# PIC32MK1024GPK064 device description
Architecture: MIPS; Family: PIC32MK; Series: PIC32MK
Registers are 32-bit, read-write, no defined reset value unless marked. A register's access mark holds for its fields unless they carry their own. Offsets are from the block's base; [hi:lo] are bit positions; {n}, {i} and the like mark numbered series; 'fields as' and 'values as' point back to an identical list; <NAME> marks a mode.

## CRU
Instances: CRU 0x1f801200 in periph_pb1_std
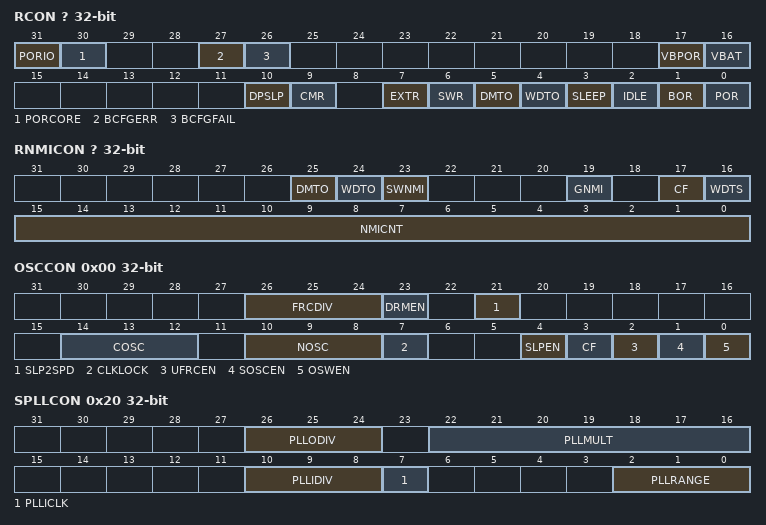
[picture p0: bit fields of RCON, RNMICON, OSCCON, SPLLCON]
? RCON size not given access not given — Reset Control Register
  [31] PORIO — I/O Voltage POR Flag bit
    1=RESET (A Power-up Reset has occurred due to I/O Voltage); 0=NORESET (A Power-up Reset has not occurred due to I/O Voltage)
  [30] PORCORE — Core Voltage POR Flag bit
    1=RESET (A Power-up Reset has occurred due to Core Voltage); 0=NORESET (A Power-up Reset has not occurred due to Core Voltage)
  [27] BCFGERR — Primary Configuration Registers Error Flag bit
    1=ERROR (An error occurred during a read of the primary configuration registers); 0=NOERROR (No error occurred during a read of the primary configuration registers)
  [26] BCFGFAIL — Primary/Secondary Configuration Registers Error Flag bit
    1=ERROR (An error occurred during a read of the primary and alternate configuration registers); 0=NOERROR (No error occurred during a read of the primary and alternate configuration registers)
  [17] VBPOR — VBPOR Mode Flag bit
    1=POR (A VBAT domain POR has occurred); 0=NOPOR (A VBAT domain POR has not occurred)
  [16] VBAT — VBAT Mode Flag bit
    1=POR (A POR exit from VBAT has occurred); 0=NOPOR (A POR exit from VBAT has not occurred)
  [10] DPSLP — Deep Sleep Mode Flag bit
    1=SLEEP (Deep Sleep mode has occurred); 0=NOSLEEP (Deep Sleep mode has not occurred)
  [9] CMR — Configuration Mismatch Reset Flag bit
    1=RESET (A Configuration Mismatch Reset has occurred); 0=NORESET (A Configuration Mismatch Reset has not occurred)
  [7] EXTR — External Reset (MCLR) Pin Flag bit
    1=RESET (Master Clear (pin) Reset has occurred); 0=NORESET (Master Clear (pin) Reset has not occurred)
  [6] SWR — Software Reset Flag bit
    1=RESET (Software Reset was executed); 0=NORESET (Software Reset was not executed)
  [5] DMTO — Deadman Timer Time-out Flag bit
    1=TIMEOUT (A DMT time-out has occurred); 0=NOTIMEOUT (A DMT time-out has not occurred)
  [4] WDTO — Watchdog Timer Time-out Flag bit
    1=TIMEOUT (WDT Time-out has occurred); 0=NOTIMEOUT (WDT Time-out has not occurred)
  [3] SLEEP — Wake From Sleep Flag bit
    1=SLEEP (Device was in Sleep mode); 0=NOSLEEP (Device was not in Sleep mode)
  [2] IDLE — Wake From Idle Flag bit
    1=IDLE (Device was in Idle mode); 0=NOIDLE (Device was not in Idle mode)
  [1] BOR — Brown-out Reset Flag bit
    1=RESET (Brown-out Reset has occurred); 0=NORESET (Brown-out Reset has not occurred)
  [0] POR — Power-on Reset Flag bit
    1=RESET (Power-on Reset has occurred); 0=NORESET (Power-on Reset has NOT occurred)
? RSWRST size not given access not given — Software Reset Register
  [0] SWRST — Enable software Reset event
    1=RESET (Enable software Reset event); 0=NORESET (No effect)
? RNMICON size not given access not given — Non-maskable Interrupt Control Register
  [25] DMTO — Deadman Timer Time-out Flag bit
    1=TIMEOUT (DMT time-out has occurred and caused a NMI); 0=NO_TIMEOUT (DMT time-out has not occurred)
  [24] WDTO — Watchdog Timer Time-Out Flag bit
    1=TIMEOUT (WDT time-out has occurred and caused a NMI); 0=NO_TIMEOUT (WDT time-out has not occurred)
  [23] SWNMI — Software NMI Trigger
    1=GENERATE_NMI (An NMI will be generated); 0=NO_NMI (An NMI will not be generated)
  [19] GNMI — General NMI bit
    1=EVENT (A general NMI event has been detected or a user-initiated NMI event has occurred); 0=NOEVENT (A general NMI event has not been detected)
  [17] CF — Clock Fail Detect bit
    1=CLKFAIL (FSCM has detected clock failure and caused an NMI); 0=NOCKFAIL (FSCM has not detected clock failure)
  [16] WDTS — Watchdog Timer Time-out in Sleep Mode Flag bit
    1=TIMEOUT (WDT time-out has occurred during Sleep mode and caused a wake-up from sleep); 0=NOTIMEOUT (WDT time-out has not occurred during Sleep mode)
  [15:0] NMICNT — NMI Reset Counter Value bits
    0=NODELAY (No delay between NMI assertion and device Reset event)
? PWRCON size not given access not given — Power Control Register
  [0] VREGS — Internal Voltage Regulator Stand-by Enable bit
    1=ACTIVE (Voltage regulator will remain active during Sleep); 0=STANDBY (Voltage regulator will go to Stand-by mode during Sleep)
0x00 OSCCON — Oscillator Control Register
  [26:24] FRCDIV — Internal Fast RC Oscillator Clock Divider bits
    7=DIV256 (FRC divided by 256); 6=DIV64 (FRC divided by 64); 5=DIV32 (FRC divided by 32); 4=DIV16 (FRC divided by 16); 3=DIV8 (FRC divided by 8); 2=DIV4 (FRC divided by 4); 1=DIV2 (FRC divided by 2); 0=DIV1 (FRC divided by 1 (default setting))
  [23] DRMEN — Dream Mode Enable bit
    1=Dream mode is enabled; 0=Dream mode is disabled
  [21] SLP2SPD — Sleep Two-speed Start-up Control bit
    1=Use FRC as SYSCLK until the selected clock is ready; 0=Use the selected clock directly
  [14:12] COSC — Current Oscillator Selection bits
    6=Backup Fast RC (BFRC) Oscillator; 5=Internal Low-Power RC (LPRC) Oscillator; 4=Secondary Oscillator (SOSC); 3=USB PLL (UPLL) input clock and divider are set by UPLLCON; 2=Primary Oscillator (Posc) (HS or EC); 1=System PLL (SPLL) input clock and divider set by SPLLCON; 0=Internal Fast RC (FRC) Oscillator divided by FRCDIV bits (FRCDIV) supports FRN divided by N
  [10:8] NOSC — New Oscillator Selection bits
    6=Backup Fast RC (BFRC) Oscillator; 5=Internal Low-Power RC (LPRC) Oscillator; 4=Secondary Oscillator; 3=USB PLL (UPLL) input clock and divider are set by UPLLCON; 2=Primary Oscillator (Posc) (HS or EC); 1=System PLL (SPLL) input clock and divider set by SPLLCON; 0=Internal Fast RC (FRC) Oscillator divided by FRCDIV bits (FRCDIV) supports FRN divided by N
  [7] CLKLOCK — Clock Selection Lock Enable bit
    1=Clock and PLL selections are locked; 0=Clock and PLL selections are not locked and may be modified
  [4] SLPEN — Sleep Mode Enable bit
    1=Device will enter Sleep mode when a WAIT instruction is executed; 0=Device will enter Idle mode when a WAIT instruction is executed
  [3] CF — Clock Fail Detect bit
    1=FSCM has detected a clock failure; 0=No clock failure has been detected
  [2] UFRCEN — USB FRC Sleep Clock Enable bit
    1=FRC is the USB input clock for wake from Sleep mode; 0=USB input clock is determined by the UPOSCEN bit (UPLLCON)
  [1] SOSCEN — Secondary Oscillator (
    1=Enable Secondary Oscillator; 0=Disable Secondary Oscillator
  [0] OSWEN — Oscillator Switch Enable bit
    1=Initiate an oscillator switch to selection specified by NOSC bits; 0=Oscillator switch is complete
0x10 OSCTUN — FRC Tuning Register
  [5:0] TUN — FRC Oscillator Tuning bits
    63=+1.453%; 32=0.000% (Nominal Center Frequency; 0=-1.500%
0x20 SPLLCON — System PLL Control Register
  [26:24] PLLODIV — System PLL Output Clock Divider bits
    5=DIV_32 (PLL Divide by 32); 4=DIV_16 (PLL Divide by 16); 3=DIV_8 (PLL Divide by 8); 2=DIV_4 (PLL Divide by 4); 1=DIV_2 (PLL Divide by 2)
  [22:16] PLLMULT — System PLL Multiplier bits
    {v}=MUL_{v+1} (Multiply by {v+1}) (v=0..127)
  [10:8] PLLIDIV — System PLL Input Clock Divider bits
    {v}=DIV_{v+1} (Divide by {v+1}) (v=0..7)
  [7] PLLICLK — System PLL Input Clock Source bit
    1=FRC is selected as the input to the System PLL; 0=Posc is selected as the input to the System PLL
  [2:0] PLLRANGE — System PLL Frequency Range Selection bits
    6=RANGE_54_64_MHZ (54-64 MHz); 5=RANGE_34_64_MHZ (34-64 MHz); 4=RANGE_21_42_MHZ (21-42 MHz); 3=RANGE_13_26_MHZ (13-26 MHz); 2=RANGE_8_16_MHZ (8-16 MHz); 1=RANGE_5_10_MHZ (5-10 MHz); 0=Bypass
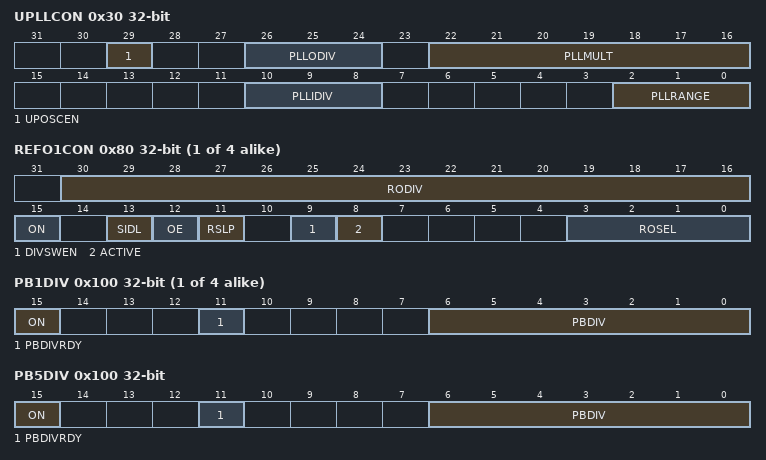
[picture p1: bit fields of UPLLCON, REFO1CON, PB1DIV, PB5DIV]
0x30 UPLLCON — USB PLL Control Register
  [29] UPOSCEN — Output Enable bit
    1=POSC (USB input clock is Posc); 0=UPLL (USB input clock is UPLL)
  [26:24] PLLODIV — System PLL Output Clock Divider bits
    values as SPLLCON.PLLODIV
  [22:16] PLLMULT — System PLL Multiplier Output Clock Divider bits
    {v}=MUL_{v+1} (Multiply by {v+1}) (v=0..127)
  [10:8] PLLIDIV — System PLL Input Clock Divider bits
    {v}=DIV_{v+1} (Divide by {v+1}) (v=0..7)
  [2:0] PLLRANGE — System PLL Frequency Range Selection bits
    6=RANGE_54_90_MHZ (54-90 MHz); 5=RANGE_34_64_MHZ (34-68 MHz); 4=RANGE_21_42_MHZ (21-42 MHz); 3=RANGE_13_26_MHZ (13-26 MHz); 2=RANGE_8_16_MHZ (8-16 MHz); 1=RANGE_5_10_MHZ (5-10 MHz); 0=Bypass
{0x60+0x20*i} REFO{i}CON (i=1..4) — Reference Oscillator Control Register
  [30:16] RODIV — Reference Clock Divider bits
  [15] ON — Output Enable bit
    1=Reference Oscillator Module enabled; 0=Reference Oscillator Module disabled
  [13] SIDL — Peripheral Stop in Idle Mode bit
    1=Discontinue module operation when the device enters Idle mode; 0=Continue module operation in Idle mode
  [12] OE — Reference Clock Output Enable bit
    1=Reference clock is driven out on REFCLKOx pin; 0=Reference clock is not driven out on REFCLKOx pin
  [11] RSLP — Reference Oscillator Module Run in Sleep bit
    1=Reference Oscillator Module output continues to run in Sleep; 0=Reference Oscillator Module output is disabled in Sleep
  [9] DIVSWEN — Divider Switch Enable bit
    1=Divider switch is in progress; 0=Divider switch is complete
  [8] ACTIVE — Reference Clock Request Status bit
    1=Reference clock request is active; 0=Reference clock request is not active
  [3:0] ROSEL — Reference Clock Source Select bits
    8=REFCLKI (Reference Clock Input REFCLKI); 7=SPLL (System PLL Output SPLL); 6=UPLL (USB PLL UPLL); 5=Sosc (Secondary Oscillator SOSC); 4=LPRC (Low Power Oscillator LPRC); 3=FRC (Internal Fast Oscillator FRC); 2=Posc (Primary Oscillator POSC); 1=PBCLK1 (Peripheral Clock 1 PBCLK1); 0=SYSCLK (System clock SYSCLK)
{0x70+0x20*i} REFO{i}TRIM (i=1..4) — Reference Oscillator Trim Register (x = 1-4)
  [31:23] ROTRIM — Reference Oscillator Trim bits
    0x1ff=511/512 divisor added to RODIV value; 0x1fe=510/512 divisor added to RODIV value; 0x100=256/512 divisor added to RODIV value; 2=2/512 divisor added to RODIV value; 1=1/512 divisor added to RODIV value; 0=0 divisor added to RODIV value
{0xF0+0x10*i} PB{i}DIV (i=1..4) — Peripheral Bus x Clock Divisor Control Register (x = 1-7)
  [15] ON — Peripheral Bus x Output Clock Enable bit
    1=Output clock is enabled; 0=Output clock is disabled
  [11] PBDIVRDY — Peripheral Bus x Clock Divisor Ready bit
    1=Clock divisor logic is not switching divisors and the PBxDIV bits may be written; 0=Clock divisor logic is currently switching values and the PBxDIV bits cannot be written
  [6:0] PBDIV — Peripheral Bus x Clock Divisor Control bits
    127=PBCLKx is SYSCLK divided by 128; 126=PBCLKx is SYSCLK divided by 127; 3=PBCLKx is SYSCLK divided by 4 (default value for x = 6); 2=PBCLKx is SYSCLK divided by 3; 1=PBCLKx is SYSCLK divided by 2 (default value for x < 6); 0=PBCLKx is SYSCLK divided by 1 (default value for x = 7)
0x100 PB5DIV — Peripheral Bus x Clock Divisor Control Register (x = 1-7)
  fields as PB1DIV
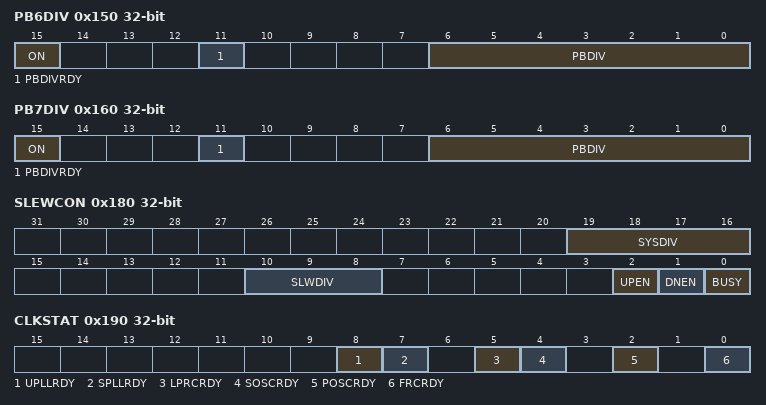
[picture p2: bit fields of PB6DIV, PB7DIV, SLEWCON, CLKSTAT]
0x150 PB6DIV — Peripheral Bus x Clock Divisor Control Register (x = 1-7)
  fields as PB1DIV
0x160 PB7DIV — Peripheral Bus x Clock Divisor Control Register (x = 1-7)
  fields as PB1DIV
0x180 SLEWCON — Oscillator Slew Control Register
  [19:16] SYSDIV — System Clock Divide Control bits
    {v}=SYSCLK is divided by {v+1} (v=1..15); 0=SYSCLK is not divided
  [10:8] SLWDIV — Slew Divisor Steps Control bits
    7=Steps are divide by 128, 64, 32, 16, 8, 4, 2, and then no divisor; 6=Steps are divide by 64, 32, 16, 8, 4, 2, and then no divisor; 5=Steps are divide by 32, 16, 8, 4, 2, and then no divisor; 4=Steps are divide by 16, 8, 4, 2, and then no divisor; 3=Steps are divide by 8, 4, 2, and then no divisor; 2=Steps are divide by 4, 2, and then no divisor; 1=Steps are divide by 2, and then no divisor; 0=No divisor is used during slewing
  [2] UPEN — Upward Slew Enable bit
    1=Slewing enabled for switching to a higher frequency; 0=Slewing disabled for switching to a higher frequency
  [1] DNEN — Downward Slew Enable bit
    1=Slewing enabled for switching to a lower frequency; 0=Slewing disabled for switching to a lower frequency
  [0] BUSY — Clock Switching Slewing Active Status bit
    1=Clock frequency is being actively slewed to the new frequency; 0=Clock switch has reached its final value
0x190 CLKSTAT ro — Oscillator Clock Status Register
  [8] UPLLRDY — USB PLL (UPLL) Ready Status bit
    1=UPLL is ready; 0=UPLL is not ready
  [7] SPLLRDY — System PLL Ready Status bit
    1=SPLL is ready; 0=SPLL is not ready
  [5] LPRCRDY — Low-Power RC Oscillator Ready Status bit
    1=LPRC is stable and ready; 0=LPRC is disabled or not operating
  [4] SOSCRDY — Secondary Oscillator Ready Status bit
    1=Sosc is stable and ready; 0=Sosc is disabled or not operating
  [2] POSCRDY — Primary Oscillator Ready Status bit
    1=Posc is stable and ready; 0=Posc is disabled or not operating
  [0] FRCRDY — Fast RC Oscillator Ready Status bit
    1=FRC is stable and ready; 0=FRC is disabled for not operating
Value list REFO1CON__RODIV: 0x7fff=REFO clock is Base clock frequency divided by 65534; 3=REFO clock is Base clock frequency divided by 6 (3*2); 2=REFO clock is Base clock frequency divided by 4 (2*2); 1=REFO clock is Base clock frequency divided by 2 (1*2); 0=REFO is the same frequency as Base Clock (no divider)
